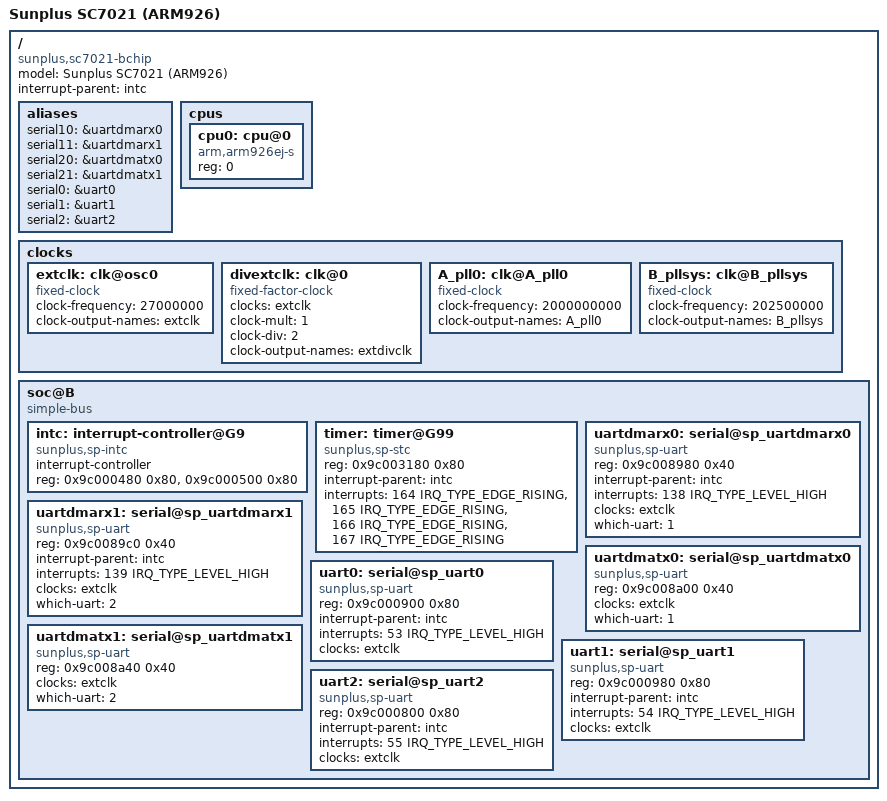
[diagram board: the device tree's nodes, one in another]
/dts-v1/;

#include "skeleton.dtsi"

#include <dt-bindings/interrupt-controller/irq.h>

#define ENABLE_DMARX0
#define ENABLE_DMARX1
#define ENABLE_DMATX0
#define ENABLE_DMATX1

/ {
	model = "Sunplus SC7021 (ARM926)";
	compatible = "sunplus,sc7021-bchip";

	interrupt-parent = <&intc>;

	aliases {
#ifdef ENABLE_DMARX0
		serial10 = &uartdmarx0;
#endif
#ifdef ENABLE_DMARX1
		serial11 = &uartdmarx1;
#endif
#ifdef ENABLE_DMATX0
		serial20 = &uartdmatx0;
#endif
#ifdef ENABLE_DMATX1
		serial21 = &uartdmatx1;
#endif

		serial0 = &uart0;
		serial1 = &uart1;
		serial2 = &uart2;
	};

	cpus {
		#address-cells = <1>;
		#size-cells = <0>;

		cpu0: cpu@0 {
			compatible = "arm,arm926ej-s";
			device_type = "cpu";
			reg = <0>;
		};
	};

	clocks {
                #address-cells = <1>;
                #size-cells = <1>;
                ranges;

		extclk: clk@osc0 {
			#clock-cells = <0>;
			compatible = "fixed-clock";
			clock-frequency = <27000000>;
			clock-output-names = "extclk";
		};

		divextclk: clk@0 {
			#clock-cells = <0>;
			compatible = "fixed-factor-clock";
			clocks  = <&extclk>;
			clock-mult = <1>;
			clock-div = <2>;
			clock-output-names = "extdivclk";
		};

		A_pll0: clk@A_pll0 {
			#clock-cells = <0>;
			compatible = "fixed-clock";
			clock-frequency = <2000000000>;
			clock-output-names = "A_pll0";
		};

		B_pllsys: clk@B_pllsys {
			#clock-cells = <0>;
			compatible = "fixed-clock";
			clock-frequency = <202500000>;
			clock-output-names = "B_pllsys";
		};
	};

	soc@B {
		compatible = "simple-bus";
		#address-cells = <1>;
		#size-cells = <1>;
		ranges;

		intc: interrupt-controller@G9 {
			compatible = "sunplus,sp-intc";
			interrupt-controller;
			#interrupt-cells = <2>;
			reg = <0x9c000480 0x80>, /* G9  */
			      <0x9c000500 0x80>; /* G10 */
		};

		/* STC_AV2 */
		timer: timer@G99 {
			compatible = "sunplus,sp-stc";
			reg = <0x9c003180 0x80>;
			interrupt-parent = <&intc>;
			interrupts =
				<164 IRQ_TYPE_EDGE_RISING>, /* AV2 timer0 */
				<165 IRQ_TYPE_EDGE_RISING>, /* AV2 timer1 */
				<166 IRQ_TYPE_EDGE_RISING>, /* AV2 timer2 */
				<167 IRQ_TYPE_EDGE_RISING>; /* AV2 timer3 */
		};

#ifdef ENABLE_DMARX0
		/* DMA Rx for UARTx */
		uartdmarx0: serial@sp_uartdmarx0 {
			compatible = "sunplus,sp-uart";
			reg = <0x9c008980 0x40>;
			interrupt-parent = <&intc>;
			interrupts = <138 IRQ_TYPE_LEVEL_HIGH>;
			clocks = <&extclk>;
			which-uart = <1>;
		};
#endif
#ifdef ENABLE_DMARX1
		uartdmarx1: serial@sp_uartdmarx1 {
			compatible = "sunplus,sp-uart";
			reg = <0x9c0089c0 0x40>;
			interrupt-parent = <&intc>;
			interrupts = <139 IRQ_TYPE_LEVEL_HIGH>;
			clocks = <&extclk>;
			which-uart = <2>;
		};
#endif
#ifdef ENABLE_DMATX0
		/* DMA Tx for UARTx */
		uartdmatx0: serial@sp_uartdmatx0 {
			compatible = "sunplus,sp-uart";
			reg = <0x9c008a00 0x40>;
			clocks = <&extclk>;
			which-uart = <1>;
		};
#endif
#ifdef ENABLE_DMATX1
		uartdmatx1: serial@sp_uartdmatx1 {
			compatible = "sunplus,sp-uart";
			reg = <0x9c008a40 0x40>;
			clocks = <&extclk>;
			which-uart = <2>;
		};
#endif


		uart0: serial@sp_uart0 {
			compatible = "sunplus,sp-uart";
			reg = <0x9c000900 0x80>;
			interrupt-parent = <&intc>;
			interrupts = <53 IRQ_TYPE_LEVEL_HIGH>;
			clocks = <&extclk>;
		};

		uart1: serial@sp_uart1 {
			compatible = "sunplus,sp-uart";
			reg = <0x9c000980 0x80>;
			interrupt-parent = <&intc>;
			interrupts = <54 IRQ_TYPE_LEVEL_HIGH>;
			clocks = <&extclk>;
		};

		uart2: serial@sp_uart2 {
			compatible = "sunplus,sp-uart";
			reg = <0x9c000800 0x80>;
			interrupt-parent = <&intc>;
			interrupts = <55 IRQ_TYPE_LEVEL_HIGH>;
			clocks = <&extclk>;
		};

	};
};
